# ES32F0xx register map
File version: 1.0
Registers are 32-bit, read-write, reset 0x0 unless marked. A register's access mark holds for its fields unless they carry their own. Offsets are from the block's base; [hi:lo] are bit positions; {n}, {i} and the like mark numbered series.

## I2C0 — I2C Interface
Base 0x40008000
Same registers: I2C1 0x40008400
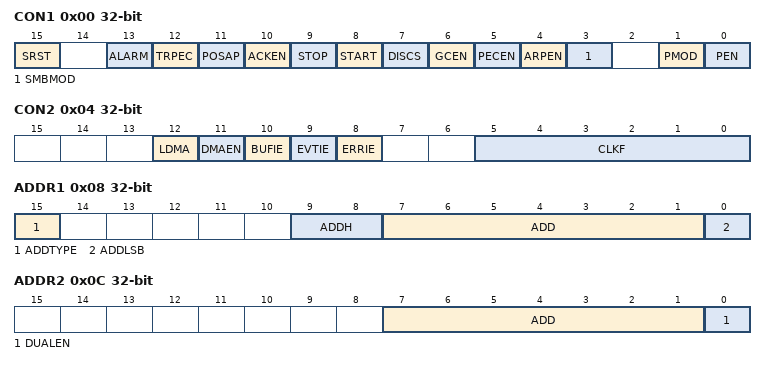
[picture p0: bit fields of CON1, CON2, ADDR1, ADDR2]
0x00 CON1
  [15] SRST, [13] ALARM, [12] TRPEC, [11] POSAP, [10] ACKEN, [9] STOP, [8] START, [7] DISCS, [6] GCEN, [5] PECEN, [4] ARPEN, [3] SMBMOD, [1] PMOD, [0] PEN
0x04 CON2
  [12] LDMA, [11] DMAEN, [10] BUFIE, [9] EVTIE, [8] ERRIE, [5:0] CLKF
0x08 ADDR1
  [15] ADDTYPE, [9:8] ADDH, [7:1] ADD, [0] ADDLSB
0x0C ADDR2
  [7:1] ADD, [0] DUALEN
0x10 DATA
  [7:0] TRBUF
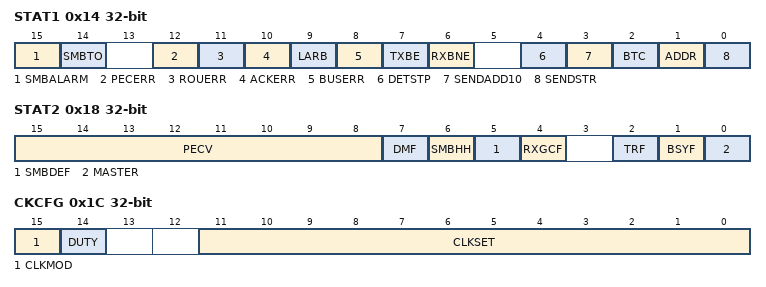
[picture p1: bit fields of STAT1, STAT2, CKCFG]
0x14 STAT1 read
  [15] SMBALARM, [14] SMBTO, [12] PECERR, [11] ROUERR, [10] ACKERR, [9] LARB, [8] BUSERR, [7] TXBE, [6] RXBNE, [4] DETSTP, [3] SENDADD10, [2] BTC, [1] ADDR, [0] SENDSTR
0x18 STAT2 read
  [15:8] PECV, [7] DMF, [6] SMBHH, [5] SMBDEF, [4] RXGCF, [2] TRF, [1] BSYF, [0] MASTER
0x1C CKCFG
  [15] CLKMOD, [14] DUTY, [11:0] CLKSET
0x20 RT
  [5:0] RISET

## CALC — Calculate
Base 0x40085400
0x00 SQRTSR read
  [0] BUSY
0x04 RDCND
  [31:0] RADICAND
0x08 SQRTRES read
  [15:0] RESULT
0x20 DIVDR
  [31:0] DIVD
0x24 DIVSR
  [31:0] DIVS
0x28 DIVQR read
  [31:0] DIVQ
0x2C DIVRR read
  [31:0] DIVS
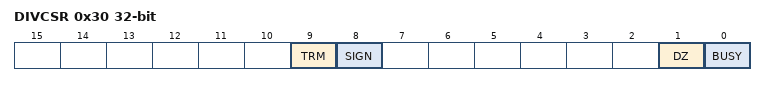
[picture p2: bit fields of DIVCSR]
0x30 DIVCSR read
  [9] TRM, [8] SIGN, [1] DZ, [0] BUSY

## CRC — Calculate CRC
Base 0x40085000
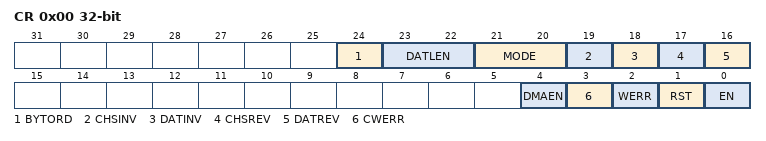
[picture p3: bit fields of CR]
0x00 CR
  [24] BYTORD, [23:22] DATLEN, [21:20] MODE, [19] CHSINV, [18] DATINV, [17] CHSREV, [16] DATREV, [4] DMAEN, [3] CWERR, [2] WERR, [1] RST, [0] EN
0x04 DATA
0x08 SEED reset 0xFFFFFFFF
0x0C CHECKSUM read

## CRYPT
Base 0x40085800
{0x0+4i} DATA{i} (i=0..3)
{0x10+4i} KEY{i} (i=0..7)
{0x30+4i} IV{i} (i=0..3)
{0x40+4i} RES{i} (i=0..3)
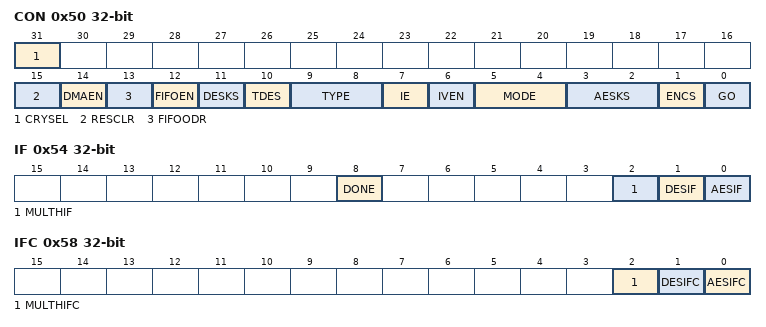
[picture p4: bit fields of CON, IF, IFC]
0x50 CON
  [31] CRYSEL, [15] RESCLR, [14] DMAEN, [13] FIFOODR, [12] FIFOEN, [11] DESKS, [10] TDES, [9:8] TYPE, [7] IE, [6] IVEN, [5:4] MODE, [3:2] AESKS, [1] ENCS, [0] GO
0x54 IF read
  [8] DONE, [2] MULTHIF, [1] DESIF, [0] AESIF
0x58 IFC write
  [2] MULTHIFC, [1] DESIFC, [0] AESIFC
0x5C FIFO

## CAN — CAN Bus
Base 0x4000B000
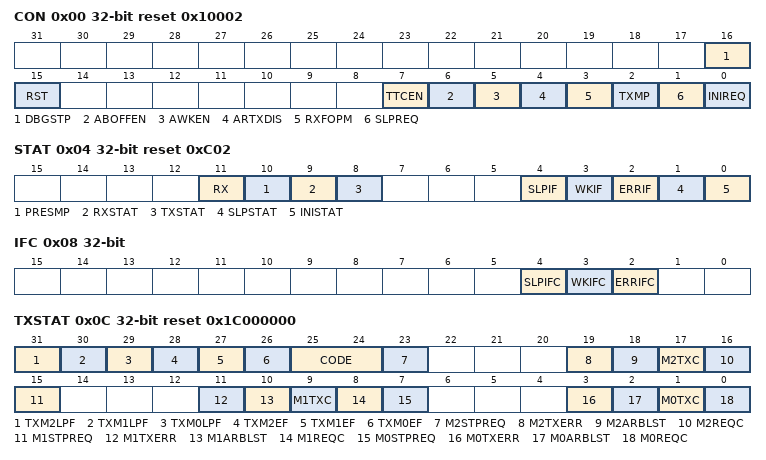
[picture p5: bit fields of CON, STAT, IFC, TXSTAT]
0x00 CON reset 0x10002
  [16] DBGSTP, [15] RST, [7] TTCEN, [6] ABOFFEN, [5] AWKEN, [4] ARTXDIS, [3] RXFOPM, [2] TXMP, [1] SLPREQ, [0] INIREQ
0x04 STAT read reset 0xC02
  [11] RX, [10] PRESMP, [9] RXSTAT, [8] TXSTAT, [4] SLPIF, [3] WKIF, [2] ERRIF, [1] SLPSTAT, [0] INISTAT
0x08 IFC write
  [4] SLPIFC, [3] WKIFC, [2] ERRIFC
0x0C TXSTAT read reset 0x1C000000
  [31] TXM2LPF, [30] TXM1LPF, [29] TXM0LPF, [28] TXM2EF, [27] TXM1EF, [26] TXM0EF, [25:24] CODE, [23] M2STPREQ, [19] M2TXERR, [18] M2ARBLST, [17] M2TXC, [16] M2REQC, [15] M1STPREQ, [11] M1TXERR, [10] M1ARBLST, [9] M1TXC, [8] M1REQC, [7] M0STPREQ, [3] M0TXERR, [2] M0ARBLST, [1] M0TXC, [0] M0REQC
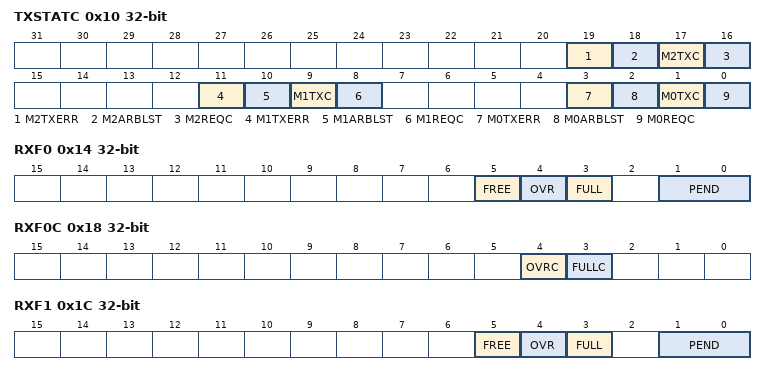
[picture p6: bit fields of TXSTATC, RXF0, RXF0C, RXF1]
0x10 TXSTATC write
  [19] M2TXERR, [18] M2ARBLST, [17] M2TXC, [16] M2REQC, [11] M1TXERR, [10] M1ARBLST, [9] M1TXC, [8] M1REQC, [3] M0TXERR, [2] M0ARBLST, [1] M0TXC, [0] M0REQC
0x14 RXF0 read
  [5] FREE, [4] OVR, [3] FULL, [1:0] PEND
0x18 RXF0C write
  [4] OVRC, [3] FULLC
0x1C RXF1 read
  [5] FREE, [4] OVR, [3] FULL, [1:0] PEND
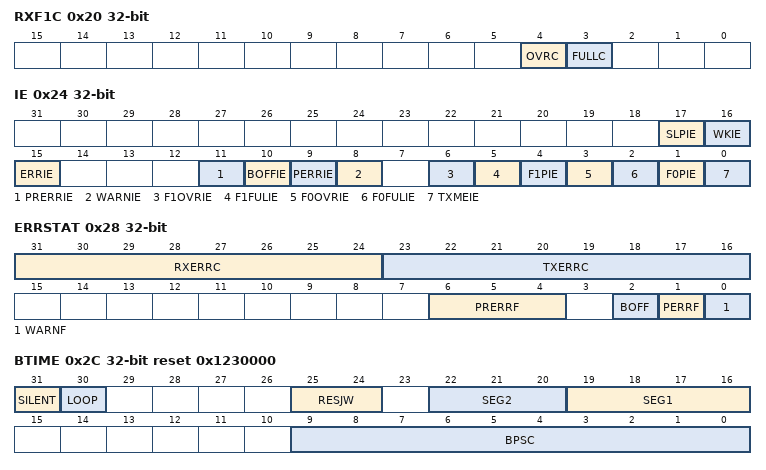
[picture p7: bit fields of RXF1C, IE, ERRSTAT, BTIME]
0x20 RXF1C read
  [4] OVRC, [3] FULLC
0x24 IE
  [17] SLPIE, [16] WKIE, [15] ERRIE, [11] PRERRIE, [10] BOFFIE, [9] PERRIE, [8] WARNIE, [6] F1OVRIE, [5] F1FULIE, [4] F1PIE, [3] F0OVRIE, [2] F0FULIE, [1] F0PIE, [0] TXMEIE
0x28 ERRSTAT read
  [31:24] RXERRC, [23:16] TXERRC, [6:4] PRERRF, [2] BOFF, [1] PERRF, [0] WARNF
0x2C BTIME reset 0x1230000
  [31] SILENT, [30] LOOP, [25:24] RESJW, [22:20] SEG2, [19:16] SEG1, [9:0] BPSC
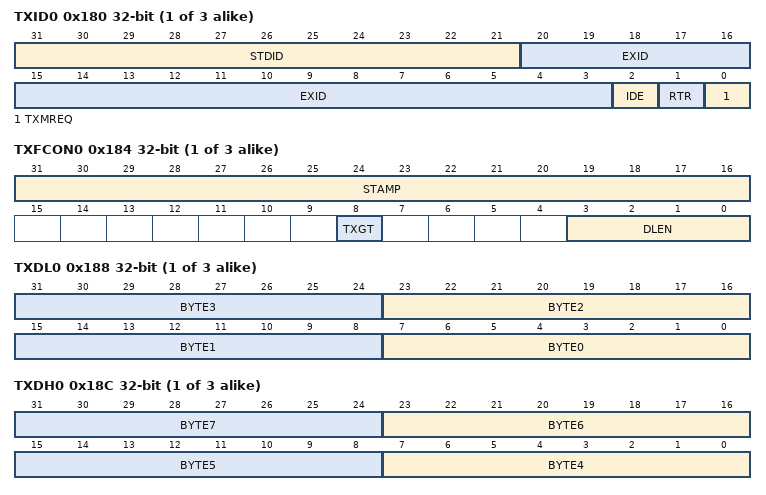
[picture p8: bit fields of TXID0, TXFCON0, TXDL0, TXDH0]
{0x180+0x10*i} TXID{i} (i=0..2)
  [31:21] STDID, [20:3] EXID, [2] IDE, [1] RTR, [0] TXMREQ
{0x184+0x10*i} TXFCON{i} (i=0..2)
  [31:16] STAMP, [8] TXGT, [3:0] DLEN
{0x188+0x10*i} TXDL{i} (i=0..2)
  [8n+7:8n] BYTE{n} (n=0..3)
{0x18C+0x10*i} TXDH{i} (i=0..2)
  [8n-25:8n-32] BYTE{n} (n=4..7)
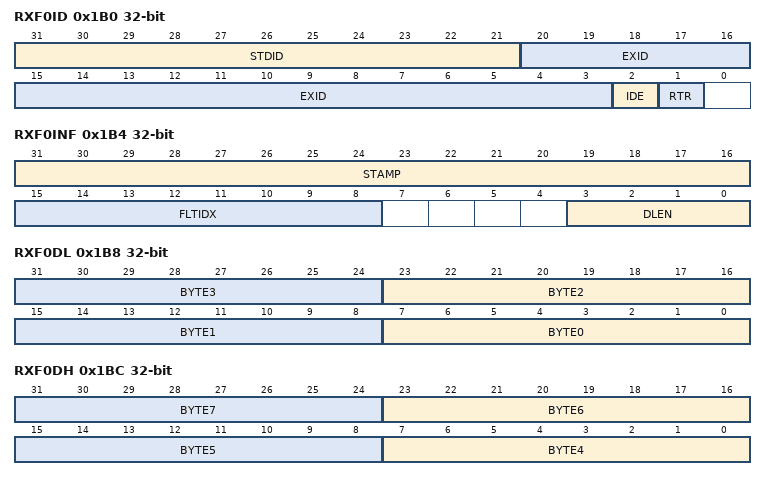
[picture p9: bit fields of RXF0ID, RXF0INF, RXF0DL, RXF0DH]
0x1B0 RXF0ID read
  [31:21] STDID, [20:3] EXID, [2] IDE, [1] RTR
0x1B4 RXF0INF read
  [31:16] STAMP, [15:8] FLTIDX, [3:0] DLEN
0x1B8 RXF0DL read
  [8n+7:8n] BYTE{n} (n=0..3)
0x1BC RXF0DH read
  [8n-25:8n-32] BYTE{n} (n=4..7)
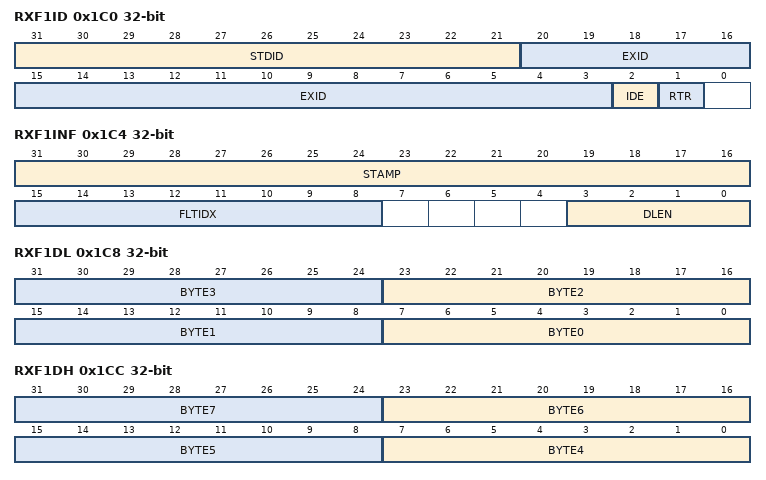
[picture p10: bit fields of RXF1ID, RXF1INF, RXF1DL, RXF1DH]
0x1C0 RXF1ID read
  [31:21] STDID, [20:3] EXID, [2] IDE, [1] RTR
0x1C4 RXF1INF read
  [31:16] STAMP, [15:8] FLTIDX, [3:0] DLEN
0x1C8 RXF1DL read
  [8n+7:8n] BYTE{n} (n=0..3)
0x1CC RXF1DH read
  [8n-25:8n-32] BYTE{n} (n=4..7)
0x200 FLTCON reset 0x2A1C0E01
  [0] FLTINI
0x204 FLTM
  [13:0] MOD
0x20C FLTWS
  [13:0] SEL
0x214 FLTAS
  [13:0] ASSIGN
0x21C FLTGO
  [13:0] GO
{0x240+8i} FLT{i}R1 (i=0..13)
  [31:0] FLTB
{0x244+8i} FLT{i}R2 (i=0..13)
  [31:0] FLTB
